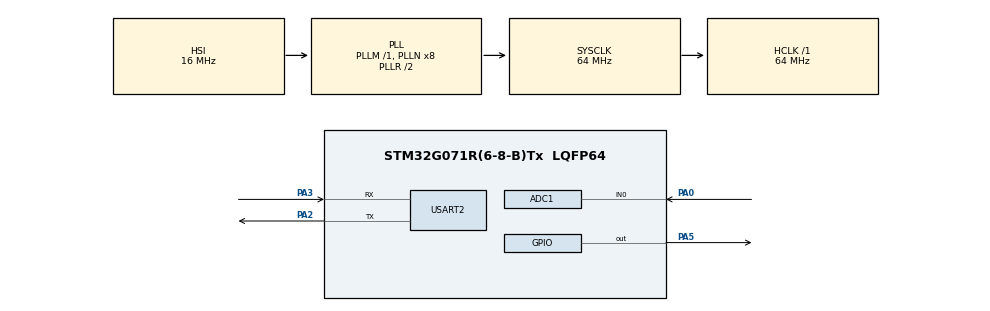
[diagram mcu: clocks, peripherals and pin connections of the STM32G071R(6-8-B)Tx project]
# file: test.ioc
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ADC1.Channel-0\#ChannelRegularConversion=ADC_CHANNEL_0
ADC1.ContinuousConvMode=ENABLE
ADC1.NbrOfConversionFlag=1
ADC1.Rank-0\#ChannelRegularConversion=1
ADC1.Resolution=ADC_RESOLUTION_8B
ADC1.SamplingTime-0\#ChannelRegularConversion=ADC_SAMPLINGTIME_COMMON_1
ADC1.master=1
Mcu.Family=STM32G0
Mcu.Name=STM32G071R(6-8-B)Tx
Mcu.Package=LQFP64
NVIC.ADC1_COMP_IRQn=true\:0\:0\:false\:false\:true\:true\:true
NVIC.USART2_IRQn=true\:0\:0\:false\:false\:true\:true\:true
PA0.Mode=IN0
PA0.Signal=ADC1_IN0
PA2.Mode=Asynchronous
PA2.Signal=USART2_TX
PA3.Mode=Asynchronous
PA3.Signal=USART2_RX
PA5.Signal=GPIO_Output
ProjectManager.HeapSize=0x200
ProjectManager.StackSize=0x400
ProjectManager.TargetToolchain=STM32CubeIDE
RCC.ADCFreq_Value=64000000
RCC.AHBFreq_Value=64000000
RCC.CortexFreq_Value=64000000
RCC.EXTERNAL_CLOCK_VALUE=48000
RCC.HCLKFreq_Value=64000000
RCC.HSE_VALUE=8000000
RCC.HSI_VALUE=16000000
RCC.LSE_VALUE=32768
RCC.SYSCLKFreq_VALUE=64000000
RCC.SYSCLKSource=RCC_SYSCLKSOURCE_PLLCLK
RCC.VCOOutputFreq_Value=128000000
USART2.VirtualMode-Asynchronous=VM_ASYNC
USART2.WordLength=WORDLENGTH_8B
board=custom

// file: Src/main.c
/* USER CODE BEGIN Header */
/**
  ******************************************************************************
  * @file           : main.c
  * @brief          : Main program body
  ******************************************************************************
  * @attention
  *
  * <h2><center>&copy; Copyright (c) 2019 STMicroelectronics.
  * All rights reserved.</center></h2>
  *
  * This software component is licensed by ST under BSD 3-Clause license,
  * the "License"; You may not use this file except in compliance with the
  * License. You may obtain a copy of the License at:
  *                        opensource.org/licenses/BSD-3-Clause
  *
  ******************************************************************************
  */
/* USER CODE END Header */

#include "main.h"

/* USER CODE BEGIN Includes */
//testing 1//
//test 2//
//checking things
/* USER CODE END Includes */
//bbb

ADC_HandleTypeDef hadc1;

UART_HandleTypeDef huart2;

void SystemClock_Config(void);
static void MX_GPIO_Init(void);
static void MX_ADC1_Init(void);
static void MX_USART2_UART_Init(void);

int main(void)
{

  /* MCU Configuration--------------------------------------------------------*/

  /* Reset of all peripherals, Initializes the Flash interface and the Systick. */
  HAL_Init();

  /* Configure the system clock */
  SystemClock_Config();

  /* Initialize all configured peripherals */
  MX_GPIO_Init();
  MX_ADC1_Init();
  MX_USART2_UART_Init();

  /* Infinite loop */
  /* USER CODE BEGIN WHILE */
  while (1)
  {
//	  HAL_UART_Transmit(&huart2,"hello",5,1000);
    /* USER CODE END WHILE */
      HAL_GPIO_TogglePin(GPIOA, GPIO_PIN_5);
      HAL_Delay(200);
  }
}

void SystemClock_Config(void)
{
  RCC_OscInitTypeDef RCC_OscInitStruct = {0};
  RCC_ClkInitTypeDef RCC_ClkInitStruct = {0};
  RCC_PeriphCLKInitTypeDef PeriphClkInit = {0};

  /** Configure the main internal regulator output voltage
  */
  HAL_PWREx_ControlVoltageScaling(PWR_REGULATOR_VOLTAGE_SCALE1);
  /** Initializes the CPU, AHB and APB busses clocks
  */
  RCC_OscInitStruct.OscillatorType = RCC_OSCILLATORTYPE_HSI;
  RCC_OscInitStruct.HSIState = RCC_HSI_ON;
  RCC_OscInitStruct.HSIDiv = RCC_HSI_DIV1;
  RCC_OscInitStruct.HSICalibrationValue = RCC_HSICALIBRATION_DEFAULT;
  RCC_OscInitStruct.PLL.PLLState = RCC_PLL_ON;
  RCC_OscInitStruct.PLL.PLLSource = RCC_PLLSOURCE_HSI;
  RCC_OscInitStruct.PLL.PLLM = RCC_PLLM_DIV1;
  RCC_OscInitStruct.PLL.PLLN = 8;
  RCC_OscInitStruct.PLL.PLLP = RCC_PLLP_DIV2;
  RCC_OscInitStruct.PLL.PLLQ = RCC_PLLQ_DIV2;
  RCC_OscInitStruct.PLL.PLLR = RCC_PLLR_DIV2;
  if (HAL_RCC_OscConfig(&RCC_OscInitStruct) != HAL_OK)
  {
    Error_Handler();
  }
  /** Initializes the CPU, AHB and APB busses clocks
  */
  RCC_ClkInitStruct.ClockType = RCC_CLOCKTYPE_HCLK|RCC_CLOCKTYPE_SYSCLK
                              |RCC_CLOCKTYPE_PCLK1;
  RCC_ClkInitStruct.SYSCLKSource = RCC_SYSCLKSOURCE_PLLCLK;
  RCC_ClkInitStruct.AHBCLKDivider = RCC_SYSCLK_DIV1;
  RCC_ClkInitStruct.APB1CLKDivider = RCC_HCLK_DIV1;

  if (HAL_RCC_ClockConfig(&RCC_ClkInitStruct, FLASH_LATENCY_2) != HAL_OK)
  {
    Error_Handler();
  }
  /** Initializes the peripherals clocks
  */
  PeriphClkInit.PeriphClockSelection = RCC_PERIPHCLK_USART2|RCC_PERIPHCLK_ADC;
  PeriphClkInit.Usart2ClockSelection = RCC_USART2CLKSOURCE_PCLK1;
  PeriphClkInit.AdcClockSelection = RCC_ADCCLKSOURCE_SYSCLK;
  if (HAL_RCCEx_PeriphCLKConfig(&PeriphClkInit) != HAL_OK)
  {
    Error_Handler();
  }
}

static void MX_ADC1_Init(void)
{

  ADC_ChannelConfTypeDef sConfig = {0};

  /** Configure the global features of the ADC (Clock, Resolution, Data Alignment and number of conversion)
  */
  hadc1.Instance = ADC1;
  hadc1.Init.ClockPrescaler = ADC_CLOCK_SYNC_PCLK_DIV2;
  hadc1.Init.Resolution = ADC_RESOLUTION_8B;
  hadc1.Init.DataAlign = ADC_DATAALIGN_RIGHT;
  hadc1.Init.ScanConvMode = ADC_SCAN_DISABLE;
  hadc1.Init.EOCSelection = ADC_EOC_SINGLE_CONV;
  hadc1.Init.LowPowerAutoWait = DISABLE;
  hadc1.Init.LowPowerAutoPowerOff = DISABLE;
  hadc1.Init.ContinuousConvMode = ENABLE;
  hadc1.Init.NbrOfConversion = 1;
  hadc1.Init.DiscontinuousConvMode = DISABLE;
  hadc1.Init.ExternalTrigConv = ADC_SOFTWARE_START;
  hadc1.Init.ExternalTrigConvEdge = ADC_EXTERNALTRIGCONVEDGE_NONE;
  hadc1.Init.DMAContinuousRequests = DISABLE;
  hadc1.Init.Overrun = ADC_OVR_DATA_PRESERVED;
  hadc1.Init.SamplingTimeCommon1 = ADC_SAMPLETIME_1CYCLE_5;
  hadc1.Init.SamplingTimeCommon2 = ADC_SAMPLETIME_1CYCLE_5;
  hadc1.Init.OversamplingMode = DISABLE;
  hadc1.Init.TriggerFrequencyMode = ADC_TRIGGER_FREQ_HIGH;
  if (HAL_ADC_Init(&hadc1) != HAL_OK)
  {
    Error_Handler();
  }
  /** Configure Regular Channel
  */
  sConfig.Channel = ADC_CHANNEL_0;
  sConfig.Rank = ADC_REGULAR_RANK_1;
  sConfig.SamplingTime = ADC_SAMPLINGTIME_COMMON_1;
  if (HAL_ADC_ConfigChannel(&hadc1, &sConfig) != HAL_OK)
  {
    Error_Handler();
  }

}

static void MX_USART2_UART_Init(void)
{

  huart2.Instance = USART2;
  huart2.Init.BaudRate = 115200;
  huart2.Init.WordLength = UART_WORDLENGTH_8B;
  huart2.Init.StopBits = UART_STOPBITS_1;
  huart2.Init.Parity = UART_PARITY_NONE;
  huart2.Init.Mode = UART_MODE_TX_RX;
  huart2.Init.HwFlowCtl = UART_HWCONTROL_NONE;
  huart2.Init.OverSampling = UART_OVERSAMPLING_16;
  huart2.Init.OneBitSampling = UART_ONE_BIT_SAMPLE_DISABLE;
  huart2.Init.ClockPrescaler = UART_PRESCALER_DIV1;
  huart2.AdvancedInit.AdvFeatureInit = UART_ADVFEATURE_NO_INIT;
  if (HAL_UART_Init(&huart2) != HAL_OK)
  {
    Error_Handler();
  }
  if (HAL_UARTEx_SetTxFifoThreshold(&huart2, UART_TXFIFO_THRESHOLD_1_8) != HAL_OK)
  {
    Error_Handler();
  }
  if (HAL_UARTEx_SetRxFifoThreshold(&huart2, UART_RXFIFO_THRESHOLD_1_8) != HAL_OK)
  {
    Error_Handler();
  }
  if (HAL_UARTEx_DisableFifoMode(&huart2) != HAL_OK)
  {
    Error_Handler();
  }

}

static void MX_GPIO_Init(void)
{
  GPIO_InitTypeDef GPIO_InitStruct = {0};

  /* GPIO Ports Clock Enable */
  __HAL_RCC_GPIOA_CLK_ENABLE();

  /*Configure GPIO pin Output Level */
  HAL_GPIO_WritePin(GPIOA, GPIO_PIN_5, GPIO_PIN_RESET);

  /*Configure GPIO pin : PA5 */
  GPIO_InitStruct.Pin = GPIO_PIN_5;
  GPIO_InitStruct.Mode = GPIO_MODE_OUTPUT_PP;
  GPIO_InitStruct.Pull = GPIO_NOPULL;
  GPIO_InitStruct.Speed = GPIO_SPEED_FREQ_LOW;
  HAL_GPIO_Init(GPIOA, &GPIO_InitStruct);

}

void Error_Handler(void)
{
}

/************************ (C) COPYRIGHT STMicroelectronics *****END OF FILE****/
